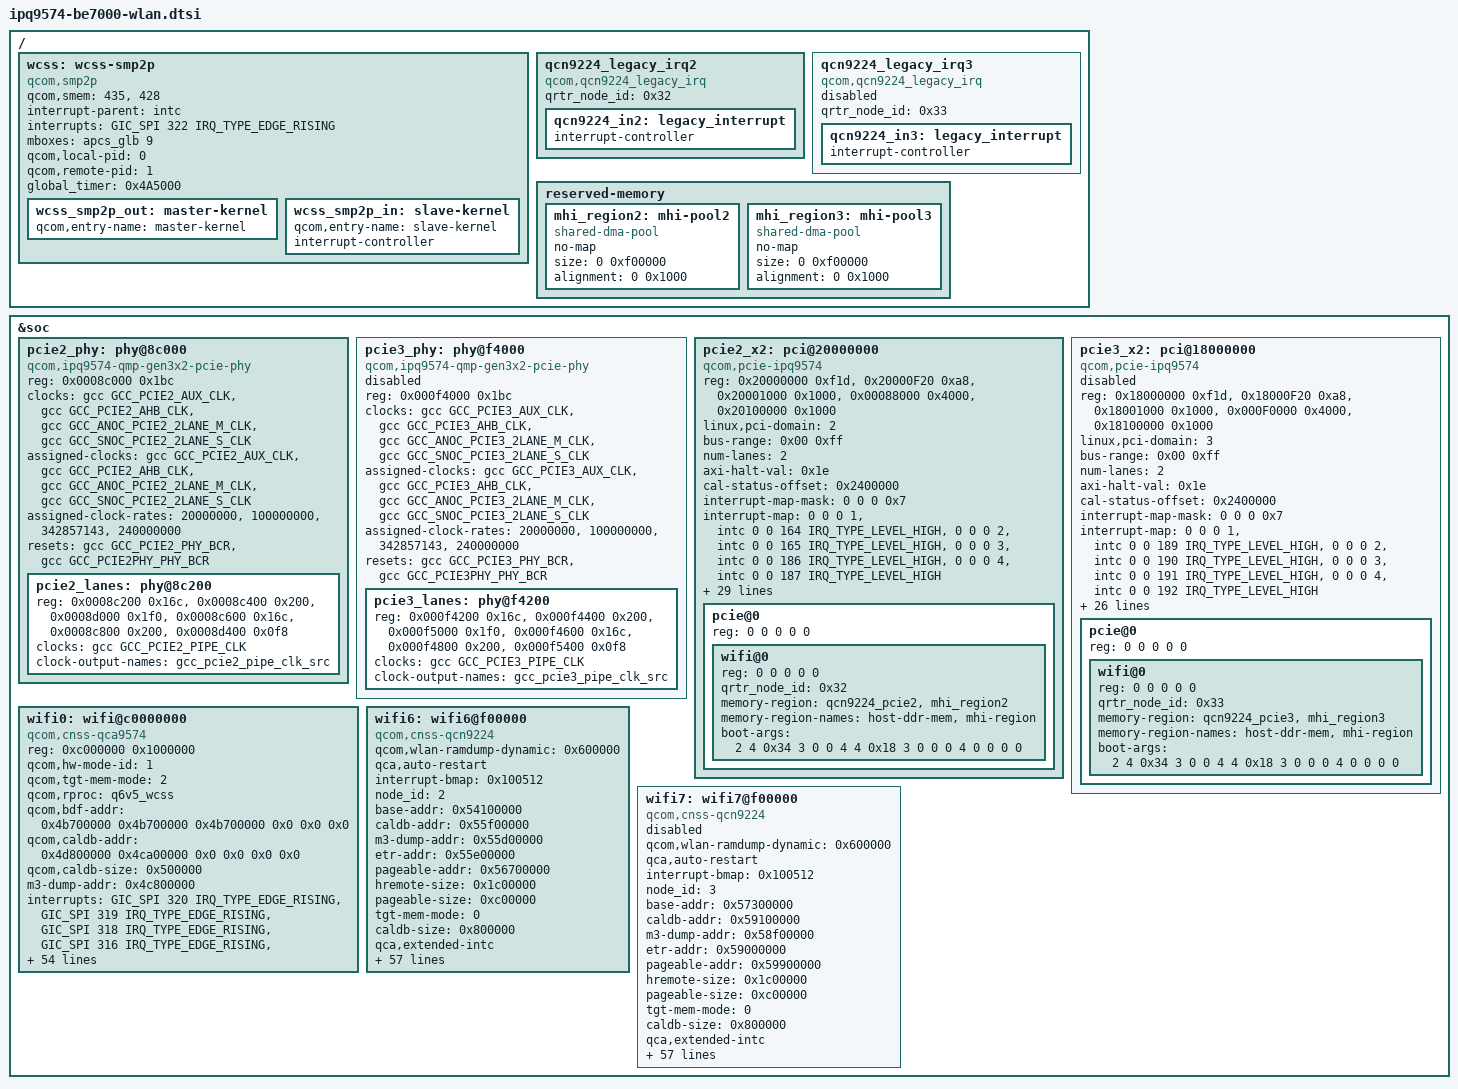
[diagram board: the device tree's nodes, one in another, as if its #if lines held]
// SPDX-License-Identifier: (GPL-2.0+ OR BSD-3-Clause)
/* IPQ9574 QSDK WLAN bindings, from NHSS.QSDK.14.0-01622-O.
 * Copyright (c) 2021-2024 Qualcomm Innovation Center, Inc. All rights reserved.
 */
/ {
	wcss: wcss-smp2p {
		compatible = "qcom,smp2p";
		qcom,smem = <435>, <428>;

		interrupt-parent = <&intc>;
		interrupts = <GIC_SPI 322 IRQ_TYPE_EDGE_RISING>;

		mboxes = <&apcs_glb 9>;

		qcom,local-pid = <0>;
		qcom,remote-pid = <1>;
		global_timer = <0x4A5000>;

		wcss_smp2p_out: master-kernel {
			qcom,entry-name = "master-kernel";
			#qcom,smem-state-cells = <1>;
		};

		wcss_smp2p_in: slave-kernel {
			qcom,entry-name = "slave-kernel";
			interrupt-controller;
			#interrupt-cells = <2>;
		};
	};
	qcn9224_legacy_irq2: qcn9224_legacy_irq2 {
		compatible = "qcom,qcn9224_legacy_irq";
		qrtr_node_id = <0x32>;
		status = "okay";

		qcn9224_in2: legacy_interrupt {
			interrupt-controller;
			#interrupt-cells = <2>;
		};
	};
	qcn9224_legacy_irq3: qcn9224_legacy_irq3 {
		compatible = "qcom,qcn9224_legacy_irq";
		qrtr_node_id = <0x33>;
		status = "disabled";

		qcn9224_in3: legacy_interrupt {
			interrupt-controller;
			#interrupt-cells = <2>;
		};
	};
};
&soc {
		pcie2_phy: phy@8c000 {
			compatible = "qcom,ipq9574-qmp-gen3x2-pcie-phy";
			reg = <0x0008c000 0x1bc>; /* Serdes PLL */
			#address-cells = <1>;
			#size-cells = <1>;
			ranges;

			clocks = <&gcc GCC_PCIE2_AUX_CLK>,
				 <&gcc GCC_PCIE2_AHB_CLK>,
				 <&gcc GCC_ANOC_PCIE2_2LANE_M_CLK>,
				 <&gcc GCC_SNOC_PCIE2_2LANE_S_CLK>;
			clock-names = "aux", "cfg_ahb", "anoc_lane", "snoc_lane";

			assigned-clocks = <&gcc GCC_PCIE2_AUX_CLK>,
					  <&gcc GCC_PCIE2_AHB_CLK>,
					  <&gcc GCC_ANOC_PCIE2_2LANE_M_CLK>,
					  <&gcc GCC_SNOC_PCIE2_2LANE_S_CLK>;
			assigned-clock-rates = <20000000>,
					       <100000000>,
					       <342857143>,
					       <240000000>;

			resets = <&gcc GCC_PCIE2_PHY_BCR>,
				 <&gcc GCC_PCIE2PHY_PHY_BCR>;
			reset-names = "phy", "common";

			status = "disabled";

			pcie2_lanes: phy@8c200 {
				reg = <0x0008c200 0x16c>, /* Serdes Tx0 */
				      <0x0008c400 0x200>, /* Serdes Rx0 */
				      <0x0008d000 0x1f0>, /* PCS: Lane0, COM, PCIE */
				      <0x0008c600 0x16c>, /* Serdes Tx1 */
				      <0x0008c800 0x200>, /* Serdes Rx1 */
				      <0x0008d400 0x0f8>; /* pcs_misc */

				#phy-cells = <0>;

				clocks = <&gcc GCC_PCIE2_PIPE_CLK>;
				clock-names = "pipe0";
				clock-output-names = "gcc_pcie2_pipe_clk_src";
				#clock-cells = <0>;
			};
		};
		pcie3_phy: phy@f4000 {
			compatible = "qcom,ipq9574-qmp-gen3x2-pcie-phy";
			reg = <0x000f4000 0x1bc>; /* Serdes PLL */
			#address-cells = <1>;
			#size-cells = <1>;
			ranges;

			clocks = <&gcc GCC_PCIE3_AUX_CLK>,
				 <&gcc GCC_PCIE3_AHB_CLK>,
				 <&gcc GCC_ANOC_PCIE3_2LANE_M_CLK>,
				 <&gcc GCC_SNOC_PCIE3_2LANE_S_CLK>;
			clock-names = "aux", "cfg_ahb", "anoc_lane", "snoc_lane";

			assigned-clocks = <&gcc GCC_PCIE3_AUX_CLK>,
					  <&gcc GCC_PCIE3_AHB_CLK>,
					  <&gcc GCC_ANOC_PCIE3_2LANE_M_CLK>,
					  <&gcc GCC_SNOC_PCIE3_2LANE_S_CLK>;
			assigned-clock-rates = <20000000>,
					       <100000000>,
					       <342857143>,
					       <240000000>;

			resets = <&gcc GCC_PCIE3_PHY_BCR>,
				 <&gcc GCC_PCIE3PHY_PHY_BCR>;
			reset-names = "phy", "common";

			status = "disabled";

			pcie3_lanes: phy@f4200 {
				reg = <0x000f4200 0x16c>, /* Serdes Tx0 */
				      <0x000f4400 0x200>, /* Serdes Rx0 */
				      <0x000f5000 0x1f0>, /* PCS: Lane0, COM, PCIE */
				      <0x000f4600 0x16c>, /* Serdes Tx1 */
				      <0x000f4800 0x200>, /* Serdes Rx1 */
				      <0x000f5400 0x0f8>; /* pcs_misc */

				#phy-cells = <0>;

				clocks = <&gcc GCC_PCIE3_PIPE_CLK>;
				clock-names = "pipe0";
				clock-output-names = "gcc_pcie3_pipe_clk_src";
				#clock-cells = <0>;
			};
		};
		pcie2_x2: pci@20000000 {
			compatible = "qcom,pcie-ipq9574";
			reg =  <0x20000000 0xf1d>,
			       <0x20000F20 0xa8>,
			       <0x20001000 0x1000>,
			       <0x00088000 0x4000>,
			       <0x20100000 0x1000>;
			reg-names = "dbi", "elbi", "atu", "parf", "config";
			device_type = "pci";
			linux,pci-domain = <2>;
			bus-range = <0x00 0xff>;
			num-lanes =<2>;
			#address-cells = <3>;
			#size-cells = <2>;
			axi-halt-val = <0x1e>; /* increase halt window size to 1GB */
			cal-status-offset = <0x2400000>;

			ranges = <0x81000000 0 0x20200000 0x20200000
				  0 0x00100000   /* downstream I/O */
				  0x82000000 0 0x20300000 0x20300000
				  0 0x07d00000>; /* non-prefetchable memory */

			#interrupt-cells = <1>;
			interrupt-map-mask = <0 0 0 0x7>;
			interrupt-map = <0 0 0 1 &intc 0 0 164
					 IRQ_TYPE_LEVEL_HIGH>, /* int_a */
					<0 0 0 2 &intc 0 0 165
					 IRQ_TYPE_LEVEL_HIGH>, /* int_b */
					<0 0 0 3 &intc 0 0 186
					 IRQ_TYPE_LEVEL_HIGH>, /* int_c */
					<0 0 0 4 &intc 0 0 187
					 IRQ_TYPE_LEVEL_HIGH>; /* int_d */

			interrupts = <GIC_SPI 125 IRQ_TYPE_LEVEL_HIGH>;
			interrupt-names = "global_irq";

			/* clocks and clock-names are used to enable the clock in CBCR */
			clocks = <&gcc GCC_PCIE2_AHB_CLK>,
				 <&gcc GCC_PCIE2_AUX_CLK>,
				 <&gcc GCC_PCIE2_AXI_M_CLK>,
				 <&gcc GCC_PCIE2_AXI_S_CLK>,
				 <&gcc GCC_PCIE2_AXI_S_BRIDGE_CLK>,
				 <&gcc GCC_PCIE2_RCHNG_CLK>;
			clock-names = "ahb",
				      "aux",
				      "axi_m",
				      "axi_s",
				      "axi_bridge",
				      "rchng";

			assigned-clocks = <&gcc GCC_PCIE2_AHB_CLK>,
					  <&gcc GCC_PCIE2_AUX_CLK>,
					  <&gcc GCC_PCIE2_AXI_M_CLK>,
					  <&gcc GCC_PCIE2_AXI_S_CLK>,
					  <&gcc GCC_PCIE2_AXI_S_BRIDGE_CLK>,
					  <&gcc GCC_PCIE2_RCHNG_CLK>;
			assigned-clock-rates = <100000000>,
					       <20000000>,
					       <342857143>,
					       <240000000>,
					       <240000000>,
					       <100000000>;

			resets = <&gcc GCC_PCIE2_PIPE_ARES>,
				 <&gcc GCC_PCIE2_CORE_STICKY_ARES>,
				 <&gcc GCC_PCIE2_AXI_S_STICKY_ARES>,
				 <&gcc GCC_PCIE2_AXI_S_ARES>,
				 <&gcc GCC_PCIE2_AXI_M_STICKY_ARES>,
				 <&gcc GCC_PCIE2_AXI_M_ARES>,
				 <&gcc GCC_PCIE2_AUX_ARES>,
				 <&gcc GCC_PCIE2_AHB_ARES>;
			reset-names = "pipe",
				      "sticky",
				      "axi_s_sticky",
				      "axi_s",
				      "axi_m_sticky",
				      "axi_m",
				      "aux",
				      "ahb";

			phys = <&pcie2_lanes>;
			phy-names = "pciephy";
			interconnects = <&gcc MASTER_ANOC_PCIE2 &gcc SLAVE_ANOC_PCIE2>,
					<&gcc MASTER_SNOC_PCIE2 &gcc SLAVE_SNOC_PCIE2>;
			interconnect-names = "pcie-mem", "cpu-pcie";
			msi-parent = <&v2m0>;
			status = "disabled";
		};
		pcie3_x2: pci@18000000 {
			compatible = "qcom,pcie-ipq9574";
			reg =  <0x18000000 0xf1d>,
			       <0x18000F20 0xa8>,
			       <0x18001000 0x1000>,
			       <0x000F0000 0x4000>,
			       <0x18100000 0x1000>;
			reg-names = "dbi", "elbi", "atu", "parf", "config";
			device_type = "pci";
			linux,pci-domain = <3>;
			bus-range = <0x00 0xff>;
			num-lanes = <2>;
			#address-cells = <3>;
			#size-cells = <2>;
			axi-halt-val = <0x1e>; /* increase halt window size to 1GB */
			cal-status-offset = <0x2400000>;

			ranges = <0x81000000 0 0x18200000 0x18200000
				  0 0x00100000   /* downstream I/O */
				  0x82000000 0 0x18300000 0x18300000
				  0 0x07d00000>; /* non-prefetchable memory */

			#interrupt-cells = <1>;
			interrupt-map-mask = <0 0 0 0x7>;
			interrupt-map = <0 0 0 1 &intc 0 0 189
					 IRQ_TYPE_LEVEL_HIGH>, /* int_a */
					<0 0 0 2 &intc 0 0 190
					 IRQ_TYPE_LEVEL_HIGH>, /* int_b */
					<0 0 0 3 &intc 0 0 191
					 IRQ_TYPE_LEVEL_HIGH>, /* int_c */
					<0 0 0 4 &intc 0 0 192
					 IRQ_TYPE_LEVEL_HIGH>; /* int_d */

			interrupts = <GIC_SPI 188 IRQ_TYPE_LEVEL_HIGH>;
			interrupt-names = "global_irq";

			/* clocks and clock-names are used to enable the clock in CBCR */
			clocks = <&gcc GCC_PCIE3_AHB_CLK>,
				 <&gcc GCC_PCIE3_AUX_CLK>,
				 <&gcc GCC_PCIE3_AXI_M_CLK>,
				 <&gcc GCC_PCIE3_AXI_S_CLK>,
				 <&gcc GCC_PCIE3_AXI_S_BRIDGE_CLK>,
				 <&gcc GCC_PCIE3_RCHNG_CLK>;
			clock-names = "ahb",
				      "aux",
				      "axi_m",
				      "axi_s",
				      "axi_bridge",
				      "rchng";

			assigned-clocks = <&gcc GCC_PCIE3_AHB_CLK>,
					  <&gcc GCC_PCIE3_AUX_CLK>,
					  <&gcc GCC_PCIE3_AXI_M_CLK>,
					  <&gcc GCC_PCIE3_AXI_S_CLK>,
					  <&gcc GCC_PCIE3_AXI_S_BRIDGE_CLK>,
					  <&gcc GCC_PCIE3_RCHNG_CLK>;
			assigned-clock-rates = <100000000>,
					       <20000000>,
					       <342857143>,
					       <240000000>,
					       <240000000>,
					       <100000000>;

			resets = <&gcc GCC_PCIE3_PIPE_ARES>,
				 <&gcc GCC_PCIE3_CORE_STICKY_ARES>,
				 <&gcc GCC_PCIE3_AXI_S_STICKY_ARES>,
				 <&gcc GCC_PCIE3_AXI_S_ARES>,
				 <&gcc GCC_PCIE3_AXI_M_STICKY_ARES>,
				 <&gcc GCC_PCIE3_AXI_M_ARES>,
				 <&gcc GCC_PCIE3_AUX_ARES>,
				 <&gcc GCC_PCIE3_AHB_ARES>;
			reset-names = "pipe",
				      "sticky",
				      "axi_s_sticky",
				      "axi_s",
				      "axi_m_sticky",
				      "axi_m",
				      "aux",
				      "ahb";

			phys = <&pcie3_lanes>;
			phy-names = "pciephy";
			msi-parent = <&v2m0>;
			status = "disabled";
		};
		wifi0: wifi@c0000000 {
			compatible = "qcom,cnss-qca9574", "qcom,ipq9574-wifi";
			reg = <0xc000000 0x1000000>;
			qcom,hw-mode-id = <1>;
		#ifdef __IPQ_MEM_PROFILE_256_MB__
			qcom,tgt-mem-mode = <2>;
		#elif __IPQ_MEM_PROFILE_512_MB__
			qcom,tgt-mem-mode = <1>;
		#else
			qcom,tgt-mem-mode = <0>;
		#endif
			qcom,rproc = <&q6v5_wcss>;
			qcom,bdf-addr = <0x4b700000 0x4b700000 0x4b700000
					 0x0 0x0 0x0>;
			qcom,caldb-addr = <0x4d800000 0x4ca00000 0x0
					   0x0 0x0 0x0>;
			qcom,caldb-size = <0x500000>;
		#ifdef __IPQ_MEM_PROFILE_512_MB__
			m3-dump-addr = <0x4c800000>;
		#else
			m3-dump-addr = <0x4d600000>;
		#endif
			interrupts = <GIC_SPI 320 IRQ_TYPE_EDGE_RISING>, /* o_wcss_apps_intr[0] =  */
				<GIC_SPI 319 IRQ_TYPE_EDGE_RISING>,
				<GIC_SPI 318 IRQ_TYPE_EDGE_RISING>,
				<GIC_SPI 316 IRQ_TYPE_EDGE_RISING>,
				<GIC_SPI 315 IRQ_TYPE_EDGE_RISING>,
				<GIC_SPI 314 IRQ_TYPE_EDGE_RISING>,
				<GIC_SPI 311 IRQ_TYPE_EDGE_RISING>,
				<GIC_SPI 310 IRQ_TYPE_EDGE_RISING>,
				<GIC_SPI 411 IRQ_TYPE_EDGE_RISING>,
				<GIC_SPI 410 IRQ_TYPE_EDGE_RISING>,
				<GIC_SPI 40 IRQ_TYPE_EDGE_RISING>,
				<GIC_SPI 39 IRQ_TYPE_EDGE_RISING>,
				<GIC_SPI 302 IRQ_TYPE_EDGE_RISING>,
				<GIC_SPI 301 IRQ_TYPE_EDGE_RISING>,
				<GIC_SPI 37 IRQ_TYPE_EDGE_RISING>,
				<GIC_SPI 36 IRQ_TYPE_EDGE_RISING>,
				<GIC_SPI 296 IRQ_TYPE_EDGE_RISING>,
				<GIC_SPI 295 IRQ_TYPE_EDGE_RISING>,
				<GIC_SPI 294 IRQ_TYPE_EDGE_RISING>,
				<GIC_SPI 293 IRQ_TYPE_EDGE_RISING>,
				<GIC_SPI 292 IRQ_TYPE_EDGE_RISING>,
				<GIC_SPI 291 IRQ_TYPE_EDGE_RISING>,
				<GIC_SPI 290 IRQ_TYPE_EDGE_RISING>,
				<GIC_SPI 289 IRQ_TYPE_EDGE_RISING>,
				<GIC_SPI 288 IRQ_TYPE_EDGE_RISING>, /* o_wcss_apps_intr[25] */
				<GIC_SPI 239 IRQ_TYPE_EDGE_RISING>,
				<GIC_SPI 236 IRQ_TYPE_EDGE_RISING>,
				<GIC_SPI 235 IRQ_TYPE_EDGE_RISING>,
				<GIC_SPI 234 IRQ_TYPE_EDGE_RISING>,
				<GIC_SPI 233 IRQ_TYPE_EDGE_RISING>,
				<GIC_SPI 232 IRQ_TYPE_EDGE_RISING>,
				<GIC_SPI 231 IRQ_TYPE_EDGE_RISING>,
				<GIC_SPI 230 IRQ_TYPE_EDGE_RISING>,
				<GIC_SPI 229 IRQ_TYPE_EDGE_RISING>,
				<GIC_SPI 228 IRQ_TYPE_EDGE_RISING>,
				<GIC_SPI 224 IRQ_TYPE_EDGE_RISING>,
				<GIC_SPI 223 IRQ_TYPE_EDGE_RISING>,
				<GIC_SPI 203 IRQ_TYPE_EDGE_RISING>,
				<GIC_SPI 183 IRQ_TYPE_EDGE_RISING>,
				<GIC_SPI 180 IRQ_TYPE_EDGE_RISING>,
				<GIC_SPI 179 IRQ_TYPE_EDGE_RISING>,
				<GIC_SPI 178 IRQ_TYPE_EDGE_RISING>,
				<GIC_SPI 177 IRQ_TYPE_EDGE_RISING>,
				<GIC_SPI 176 IRQ_TYPE_EDGE_RISING>,
				<GIC_SPI 163 IRQ_TYPE_EDGE_RISING>,
				<GIC_SPI 162 IRQ_TYPE_EDGE_RISING>,
				<GIC_SPI 160 IRQ_TYPE_EDGE_RISING>,
				<GIC_SPI 414 IRQ_TYPE_EDGE_RISING>,
				<GIC_SPI 159 IRQ_TYPE_EDGE_RISING>,
				<GIC_SPI 158 IRQ_TYPE_EDGE_RISING>,
				<GIC_SPI 157 IRQ_TYPE_EDGE_RISING>,
				<GIC_SPI 156 IRQ_TYPE_EDGE_RISING>; /* o_wcss_apps_intr[51] */

			interrupt-names = "misc-pulse1",
				"misc-latch",
				"sw-exception",
				"ce0",
				"ce1",
				"ce2",
				"ce3",
				"ce4",
				"ce5",
				"ce6",
				"ce7",
				"ce8",
				"ce9",
				"ce10",
				"ce11",
				"host2wbm-desc-feed",
				"host2reo-re-injection",
				"host2reo-command",
				"host2rxdma-monitor-ring3",
				"host2rxdma-monitor-ring2",
				"host2rxdma-monitor-ring1",
				"reo2ost-exception",
				"wbm2host-rx-release",
				"reo2host-status",
				"reo2host-destination-ring4",
				"reo2host-destination-ring3",
				"reo2host-destination-ring2",
				"reo2host-destination-ring1",
				"rxdma2host-monitor-destination-mac3",
				"rxdma2host-monitor-destination-mac2",
				"rxdma2host-monitor-destination-mac1",
				"ppdu-end-interrupts-mac3",
				"ppdu-end-interrupts-mac2",
				"ppdu-end-interrupts-mac1",
				"rxdma2host-monitor-status-ring-mac3",
				"rxdma2host-monitor-status-ring-mac2",
				"rxdma2host-monitor-status-ring-mac1",
				"host2rxdma-host-buf-ring-mac3",
				"host2rxdma-host-buf-ring-mac2",
				"host2rxdma-host-buf-ring-mac1",
				"rxdma2host-destination-ring-mac3",
				"rxdma2host-destination-ring-mac2",
				"rxdma2host-destination-ring-mac1",
				"host2tcl-input-ring4",
				"host2tcl-input-ring3",
				"host2tcl-input-ring2",
				"host2tcl-input-ring1",
				"wbm2host-tx-completions-ring4",
				"wbm2host-tx-completions-ring3",
				"wbm2host-tx-completions-ring2",
				"wbm2host-tx-completions-ring1",
				"tcl2host-status-ring";

			qcom,pta-num = <0>;
			qcom,coex-mode = <0x2>;
			qcom,bt-active-time = <0x12>;
			qcom,bt-priority-time = <0x0c>;
			qcom,coex-algo = <0x2>;
			qcom,pta-priority = <0x80800505>;
			status = "disabled";
		};
		wifi6: wifi6@f00000 {
			compatible  = "qcom,cnss-qcn9224";
			qcom,wlan-ramdump-dynamic = <0x600000>;
			qca,auto-restart;
			interrupt-bmap = <0x100512>;
			node_id = <2>;
#ifdef __IPQ_MEM_PROFILE_512_MB__
			/* qcn9224 tgt-mem-mode=1 layout - 27MB
			 * +=========+==============+=========+
			 * |  Region | Start Offset |   Size  |
			 * +---------+--------------+---------+
			 * | HREMOTE |  0x50500000  |   13MB  |
			 * +---------+--------------+---------+
			 * |  Caldb  |  0x51200000  |   8MB   |
			 * +---------+--------------+---------+
			 * | M3 Dump |  0x51A00000  |   1MB   |
			 * +---------+--------------+---------+
			 * |   ETR   |  0x51B00000  |   1MB   |
			 * +---------+--------------+---------+
			 * |Pageable |  0x51C00000  |   4MB   |
			 * +==================================+
			 */
			base-addr = <0x50500000>;
			caldb-addr = <0x51200000>;
			m3-dump-addr = <0x51A00000>;
			etr-addr = <0x51B00000>;
			pageable-addr = <0x51C00000>;
			hremote-size = <0xD00000>;
			pageable-size = <0x400000>;
			tgt-mem-mode = <0x1>;
#else
			/* qcn9224 tgt-mem-mode=0 layout - 36MB
			 * +=========+==============+=========+
			 * |  Region | Start Offset |   Size  |
			 * +---------+--------------+---------+
			 * | HREMOTE |  0x52500000  |   17MB  |
			 * +---------+--------------+---------+
			 * |  Caldb  |  0x53600000  |   8MB   |
			 * +---------+--------------+---------+
			 * | M3 Dump |  0x53E00000  |   1MB   |
			 * +---------+--------------+---------+
			 * |   ETR   |  0x53F00000  |   1MB   |
			 * +---------+--------------+---------+
			 * |Pageable |  0x54000000  |   9MB   |
			 * +==================================+
			 */
			base-addr = <0x52500000>;
			caldb-addr = <0x53600000>;
			m3-dump-addr = <0x53E00000>;
			etr-addr = <0x53F00000>;
			pageable-addr = <0x54000000>;
			hremote-size = <0x1100000>;
			pageable-size = <0x900000>;
			tgt-mem-mode = <0x0>;
#endif
			caldb-size = <0x800000>;
			qca,extended-intc;
			early_cal = <&pcie2_x2>;
			interrupts-extended =
				<&qcn9224_in2 5 0>,
				<&qcn9224_in2 6 0>,
				<&qcn9224_in2 7 0>,
				<&qcn9224_in2 8 0>,
				<&qcn9224_in2 9 0>,
				<&qcn9224_in2 10 0>,
				<&qcn9224_in2 11 0>,
				<&qcn9224_in2 12 0>,
				<&qcn9224_in2 13 0>,
				<&qcn9224_in2 14 0>,
				<&qcn9224_in2 15 0>,
				<&qcn9224_in2 16 0>,
				<&qcn9224_in2 17 0>,
				<&qcn9224_in2 18 0>,
				<&qcn9224_in2 19 0>,
				<&qcn9224_in2 20 0>,
				<&qcn9224_in2 49 0>,
				<&qcn9224_in2 48 0>,
				<&qcn9224_in2 47 0>,
				<&qcn9224_in2 46 0>,
				<&qcn9224_in2 45 0>,
				<&qcn9224_in2 44 0>,
				<&qcn9224_in2 43 0>,
				<&qcn9224_in2 42 0>,
				<&qcn9224_in2 50 0>,
				<&qcn9224_in2 52 0>,
				<&qcn9224_in2 51 0>,
				<&qcn9224_in2 30 0>,
				<&qcn9224_in2 29 0>,
				<&qcn9224_in2 28 0>,
				<&qcn9224_in2 27 0>,
				<&qcn9224_in2 26 0>,
				<&qcn9224_in2 25 0>,
				<&qcn9224_in2 31 0>,
				<&qcn9224_in2 80 0>,
				<&qcn9224_in2 71 0>,
				<&qcn9224_in2 96 0>,
				<&qcn9224_in2 97 0>,
				<&qcn9224_in2 67 0>,
				<&qcn9224_in2 100 0>,
				<&qcn9224_in2 99 0>,
				<&qcn9224_in2 68 0>,
				<&qcn9224_in2 69 0>,
				<&qcn9224_in2 121 0>,
				<&qcn9224_in2 119 0>,
				<&qcn9224_in2 122 0>,
				<&qcn9224_in2 120 0>,
				<&qcn9224_in2 116 0>,
				<&qcn9224_in2 113 0>,
				<&qcn9224_in2 115 0>,
				<&qcn9224_in2 112 0>,
				<&qcn9224_in2 114 0>,
				<&qcn9224_in2 111 0>,
				<&qcn9224_in2 110 0>,
				<&qcn9224_in2 109 0>,
				<&qcn9224_in2 108 0>,
				<&qcn9224_in2 39 0>,
				<&qcn9224_in2 38 0>,
				<&qcn9224_in2 37 0>,
				<&qcn9224_in2 36 0>,
				<&qcn9224_in2 35 0>,
				<&qcn9224_in2 34 0>,
				<&qcn9224_in2 33 0>,
				<&qcn9224_in2 41 0>,
				<&qcn9224_in2 40 0>,
				<&qcn9224_in2 32 0>,
				<&qcn9224_in2 24 0>,
				<&qcn9224_in2 23 0>,
				<&qcn9224_in2 22 0>,
				<&qcn9224_in2 21 0>,
				<&qcn9224_in2 66 0>,
				<&qcn9224_in2 78 0>,
				<&qcn9224_in2 117 0>,
				<&qcn9224_in2 118 0>,
				<&qcn9224_in2 61 0>,
				<&qcn9224_in2 60 0>,
				<&qcn9224_in2 57 0>,
				<&qcn9224_in2 56 0>,
				<&qcn9224_in2 63 0>,
				<&qcn9224_in2 62 0>,
				<&qcn9224_in2 59 0>,
				<&qcn9224_in2 58 0>,
				<&qcn9224_in2 65 0>,
				<&qcn9224_in2 83 0>,
				<&qcn9224_in2 75 0>,
				<&qcn9224_in2 82 0>,
				<&qcn9224_in2 81 0>,
				<&qcn9224_in2 74 0>,
				<&qcn9224_in2 73 0>,
				<&qcn9224_in2 72 0>,
				<&qcn9224_in2 98 0>,
				<&qcn9224_in2 107 0>,
				<&qcn9224_in2 106 0>,
				<&qcn9224_in2 105 0>,
				<&qcn9224_in2 104 0>,
				<&qcn9224_in2 103 0>,
				<&qcn9224_in2 102 0>,
				<&qcn9224_in2 101 0>,
				<&qcn9224_in2 76 0>,
				<&qcn9224_in2 77 0>,
				<&qcn9224_in2 143 0>,
				<&qcn9224_in2 142 0>,
				<&qcn9224_in2 141 0>,
				<&intc GIC_SPI 164 IRQ_TYPE_LEVEL_HIGH>;

			interrupt-names = "ce0",
				"ce1",
				"ce2",
				"ce3",
				"ce4",
				"ce5",
				"ce6",
				"ce7",
				"ce8",
				"ce9",
				"ce10",
				"ce11",
				"ce12",
				"ce13",
				"ce14",
				"ce15",
				"reo2sw8_intr2",
				"reo2sw7_intr2",
				"reo2sw6_intr2",
				"reo2sw5_intr2",
				"reo2sw4_intr2",
				"reo2sw3_intr2",
				"reo2sw2_intr2",
				"reo2sw1_intr2",
				"reo2sw0_intr2",
				"reo2sw8_intr",
				"reo2sw7_intr",
				"reo2sw6_inrr",
				"reo2sw5_intr",
				"reo2sw4_intr",
				"reo2sw3_intr",
				"reo2sw2_intr",
				"reo2sw1_intr",
				"reo2sw0_intr",
				"reo2status_intr2",
				"reo_status",
				"reo2rxdma_out_2",
				"reo2rxdma_out_1",
				"reo_cmd",
				"sw2reo6",
				"sw2reo5",
				"sw2reo1",
				"sw2reo",
				"rxdma2reo_mlo_0_dst_ring1",
				"rxdma2reo_mlo_0_dst_ring0",
				"rxdma2reo_mlo_1_dst_ring1",
				"rxdma2reo_mlo_1_dst_ring0",
				"rxdma2reo_dst_ring1",
				"rxdma2reo_dst_ring0",
				"rxdma2sw_dst_ring1",
				"rxdma2sw_dst_ring0",
				"rxdma2release_dst_ring1",
				"rxdma2release_dst_ring0",
				"sw2rxdma_2_src_ring",
				"sw2rxdma_1_src_ring",
				"sw2rxdma_0",
				"wbm2sw6_release2",
				"wbm2sw5_release2",
				"wbm2sw4_release2",
				"wbm2sw3_release2",
				"wbm2sw2_release2",
				"wbm2sw1_release2",
				"wbm2sw0_release2",
				"wbm2sw6_release",
				"wbm2sw5_release",
				"wbm2sw4_release",
				"wbm2sw3_release",
				"wbm2sw2_release",
				"wbm2sw1_release",
				"wbm2sw0_release",
				"wbm2sw_link",
				"wbm_error_release",
				"sw2txmon_src_ring",
				"sw2rxmon_src_ring",
				"txmon2sw_p1_intr1",
				"txmon2sw_p1_intr0",
				"txmon2sw_p0_dest1",
				"txmon2sw_p0_dest0",
				"rxmon2sw_p1_intr1",
				"rxmon2sw_p1_intr0",
				"rxmon2sw_p0_dest1",
				"rxmon2sw_p0_dest0",
				"sw_release",
				"sw2tcl_credit2",
				"sw2tcl_credit",
				"sw2tcl4",
				"sw2tcl5",
				"sw2tcl3",
				"sw2tcl2",
				"sw2tcl1",
				"sw2wbm1",
				"misc_8",
				"misc_7",
				"misc_6",
				"misc_5",
				"misc_4",
				"misc_3",
				"misc_2",
				"misc_1",
				"misc_0",
				"mhi2",
				"mhi1",
				"mhi0",
				"inta";

			status = "disabled";
		};
		wifi7: wifi7@f00000 {
			compatible  = "qcom,cnss-qcn9224";
			qcom,wlan-ramdump-dynamic = <0x600000>;
			qca,auto-restart;
			interrupt-bmap = <0x100512>;
			node_id = <3>;
#ifdef __IPQ_MEM_PROFILE_512_MB__
			/* qcn9224 tgt-mem-mode=1 layout - 27MB
			 * +=========+==============+=========+
			 * |  Region | Start Offset |   Size  |
			 * +---------+--------------+---------+
			 * | HREMOTE |  0x52000000  |   13MB  |
			 * +---------+--------------+---------+
			 * |  Caldb  |  0x52D00000  |   8MB   |
			 * +---------+--------------+---------+
			 * | M3 Dump |  0x53500000  |   1MB   |
			 * +---------+--------------+---------+
			 * |   ETR   |  0x53600000  |   1MB   |
			 * +---------+--------------+---------+
			 * |Pageable |  0x53700000  |   4MB   |
			 * +==================================+
			 */
			base-addr = <0x52000000>;
			caldb-addr = <0x52D00000>;
			m3-dump-addr = <0x53500000>;
			etr-addr = <0x53600000>;
			pageable-addr = <0x53700000>;
			hremote-size = <0xD00000>;
			pageable-size = <0x400000>;
			tgt-mem-mode = <0x1>;
#else
			/* qcn9224 tgt-mem-mode=0 layout - 36MB
			 * +=========+==============+=========+
			 * |  Region | Start Offset |   Size  |
			 * +---------+--------------+---------+
			 * | HREMOTE |  0x54900000  |   17MB  |
			 * +---------+--------------+---------+
			 * |  Caldb  |  0x55A00000  |   8MB   |
			 * +---------+--------------+---------+
			 * | M3 Dump |  0x56200000  |   1MB   |
			 * +---------+--------------+---------+
			 * |   ETR   |  0x56300000  |   1MB   |
			 * +---------+--------------+---------+
			 * |Pageable |  0x56400000  |   9MB   |
			 * +==================================+
			 */
			base-addr = <0x54900000>;
			caldb-addr = <0x55A00000>;
			m3-dump-addr = <0x56200000>;
			etr-addr = <0x56300000>;
			pageable-addr = <0x56400000>;
			hremote-size = <0x1100000>;
			pageable-size = <0x900000>;
			tgt-mem-mode = <0x0>;
#endif
			caldb-size = <0x800000>;
			qca,extended-intc;
			early_cal = <&pcie3_x2>;
			interrupts-extended =
				<&qcn9224_in3 5 0>,
				<&qcn9224_in3 6 0>,
				<&qcn9224_in3 7 0>,
				<&qcn9224_in3 8 0>,
				<&qcn9224_in3 9 0>,
				<&qcn9224_in3 10 0>,
				<&qcn9224_in3 11 0>,
				<&qcn9224_in3 12 0>,
				<&qcn9224_in3 13 0>,
				<&qcn9224_in3 14 0>,
				<&qcn9224_in3 15 0>,
				<&qcn9224_in3 16 0>,
				<&qcn9224_in3 17 0>,
				<&qcn9224_in3 18 0>,
				<&qcn9224_in3 19 0>,
				<&qcn9224_in3 20 0>,
				<&qcn9224_in3 49 0>,
				<&qcn9224_in3 48 0>,
				<&qcn9224_in3 47 0>,
				<&qcn9224_in3 46 0>,
				<&qcn9224_in3 45 0>,
				<&qcn9224_in3 44 0>,
				<&qcn9224_in3 43 0>,
				<&qcn9224_in3 42 0>,
				<&qcn9224_in3 50 0>,
				<&qcn9224_in3 52 0>,
				<&qcn9224_in3 51 0>,
				<&qcn9224_in3 30 0>,
				<&qcn9224_in3 29 0>,
				<&qcn9224_in3 28 0>,
				<&qcn9224_in3 27 0>,
				<&qcn9224_in3 26 0>,
				<&qcn9224_in3 25 0>,
				<&qcn9224_in3 31 0>,
				<&qcn9224_in3 80 0>,
				<&qcn9224_in3 71 0>,
				<&qcn9224_in3 96 0>,
				<&qcn9224_in3 97 0>,
				<&qcn9224_in3 67 0>,
				<&qcn9224_in3 100 0>,
				<&qcn9224_in3 99 0>,
				<&qcn9224_in3 68 0>,
				<&qcn9224_in3 69 0>,
				<&qcn9224_in3 121 0>,
				<&qcn9224_in3 119 0>,
				<&qcn9224_in3 122 0>,
				<&qcn9224_in3 120 0>,
				<&qcn9224_in3 116 0>,
				<&qcn9224_in3 113 0>,
				<&qcn9224_in3 115 0>,
				<&qcn9224_in3 112 0>,
				<&qcn9224_in3 114 0>,
				<&qcn9224_in3 111 0>,
				<&qcn9224_in3 110 0>,
				<&qcn9224_in3 109 0>,
				<&qcn9224_in3 108 0>,
				<&qcn9224_in3 39 0>,
				<&qcn9224_in3 38 0>,
				<&qcn9224_in3 37 0>,
				<&qcn9224_in3 36 0>,
				<&qcn9224_in3 35 0>,
				<&qcn9224_in3 34 0>,
				<&qcn9224_in3 33 0>,
				<&qcn9224_in3 41 0>,
				<&qcn9224_in3 40 0>,
				<&qcn9224_in3 32 0>,
				<&qcn9224_in3 24 0>,
				<&qcn9224_in3 23 0>,
				<&qcn9224_in3 22 0>,
				<&qcn9224_in3 21 0>,
				<&qcn9224_in3 66 0>,
				<&qcn9224_in3 78 0>,
				<&qcn9224_in3 117 0>,
				<&qcn9224_in3 118 0>,
				<&qcn9224_in3 61 0>,
				<&qcn9224_in3 60 0>,
				<&qcn9224_in3 57 0>,
				<&qcn9224_in3 56 0>,
				<&qcn9224_in3 63 0>,
				<&qcn9224_in3 62 0>,
				<&qcn9224_in3 59 0>,
				<&qcn9224_in3 58 0>,
				<&qcn9224_in3 65 0>,
				<&qcn9224_in3 83 0>,
				<&qcn9224_in3 75 0>,
				<&qcn9224_in3 82 0>,
				<&qcn9224_in3 81 0>,
				<&qcn9224_in3 74 0>,
				<&qcn9224_in3 73 0>,
				<&qcn9224_in3 72 0>,
				<&qcn9224_in3 98 0>,
				<&qcn9224_in3 107 0>,
				<&qcn9224_in3 106 0>,
				<&qcn9224_in3 105 0>,
				<&qcn9224_in3 104 0>,
				<&qcn9224_in3 103 0>,
				<&qcn9224_in3 102 0>,
				<&qcn9224_in3 101 0>,
				<&qcn9224_in3 76 0>,
				<&qcn9224_in3 77 0>,
				<&qcn9224_in3 143 0>,
				<&qcn9224_in3 142 0>,
				<&qcn9224_in3 141 0>,
				<&intc GIC_SPI 189 IRQ_TYPE_LEVEL_HIGH>;

			interrupt-names = "ce0",
				"ce1",
				"ce2",
				"ce3",
				"ce4",
				"ce5",
				"ce6",
				"ce7",
				"ce8",
				"ce9",
				"ce10",
				"ce11",
				"ce12",
				"ce13",
				"ce14",
				"ce15",
				"reo2sw8_intr2",
				"reo2sw7_intr2",
				"reo2sw6_intr2",
				"reo2sw5_intr2",
				"reo2sw4_intr2",
				"reo2sw3_intr2",
				"reo2sw2_intr2",
				"reo2sw1_intr2",
				"reo2sw0_intr2",
				"reo2sw8_intr",
				"reo2sw7_intr",
				"reo2sw6_inrr",
				"reo2sw5_intr",
				"reo2sw4_intr",
				"reo2sw3_intr",
				"reor",
				"reo2sw1_intr",
				"reo2sw0_intr",
				"reo2status_intr2",
				"reo_status",
				"reo2rxdma_out_2",
				"reo2rxdma_out_1",
				"reo_cmd",
				"sw2reo6",
				"sw2reo5",
				"sw2reo1",
				"sw2reo",
				"rxdma2reo_mlo_0_dst_ring1",
				"rxdma2reo_mlo_0_dst_ring0",
				"rxdma2reo_mlo_1_dst_ring1",
				"rxdma2reo_mlo_1_dst_ring0",
				"rxdma2reo_dst_ring1",
				"rxdma2reo_dst_ring0",
				"rxdma2sw_dst_ring1",
				"rxdma2sw_dst_ring0",
				"rxdma2release_dst_ring1",
				"rxdma2release_dst_ring0",
				"sw2rxdma_2_src_ring",
				"sw2rxdma_1_src_ring",
				"sw2rxdma_0",
				"wbm2sw6_release2",
				"wbm2sw5_release2",
				"wbm2sw4_release2",
				"wbm2sw3_release2",
				"wbm2sw2_release2",
				"wbm2sw1_release2",
				"wbm2sw0_release2",
				"wbm2sw6_release",
				"wbm2sw5_release",
				"wbm2sw4_release",
				"wbm2sw3_release",
				"wbm2sw2_release",
				"wbm2sw1_release",
				"wbm2sw0_release",
				"wbm2sw_link",
				"wbm_error_release",
				"sw2txmon_src_ring",
				"sw2rxmon_src_ring",
				"txmon2sw_p1_intr1",
				"txmon2sw_p1_intr0",
				"txmon2sw_p0_dest1",
				"txmon2sw_p0_dest0",
				"rxmon2sw_p1_intr1",
				"rxmon2sw_p1_intr0",
				"rxmon2sw_p0_dest1",
				"rxmon2sw_p0_dest0",
				"sw_release",
				"sw2tcl_credit2",
				"sw2tcl_credit",
				"sw2tcl4",
				"sw2tcl5",
				"sw2tcl3",
				"sw2tcl2",
				"sw2tcl1",
				"sw2wbm1",
				"misc_8",
				"misc_7",
				"misc_6",
				"misc_5",
				"misc_4",
				"misc_3",
				"misc_2",
				"misc_1",
				"misc_0",
				"mhi2",
				"mhi1",
				"mhi0",
				"inta";

			status = "disabled";
		};
};

/* BE7000 stock WLAN memory pools and radio configuration. */
/ {
	reserved-memory {
		mhi_region2: mhi-pool2 {
			compatible = "shared-dma-pool";
			no-map;
			size = <0 0xf00000>;
			alignment = <0 0x1000>;
		};
		mhi_region3: mhi-pool3 {
			compatible = "shared-dma-pool";
			no-map;
			size = <0 0xf00000>;
			alignment = <0 0x1000>;
		};
	};
};

&pcie2_phy { status = "okay"; };
/* PCIe3 is disabled in this board's QFPROM fuses. */
&pcie3_phy { status = "disabled"; };
&pcie2_x2 {
	perst-gpios = <&tlmm 29 GPIO_ACTIVE_LOW>;
	status = "okay";
	pcie@0 {
		device_type = "pci";
		reg = <0 0 0 0 0>;
		#address-cells = <3>;
		#size-cells = <2>;
		ranges;
		wifi@0 {
			reg = <0 0 0 0 0>;
			qrtr_node_id = <0x32>;
			memory-region = <&qcn9224_pcie2>, <&mhi_region2>;
			memory-region-names = "host-ddr-mem", "mhi-region";
			boot-args = <2 4 0x34 3 0 0 4 4 0x18 3 0 0 0 4 0 0 0 0>;
		};
	};
};
&pcie3_x2 {
	perst-gpios = <&tlmm 32 GPIO_ACTIVE_LOW>;
	status = "disabled";
	pcie@0 {
		device_type = "pci";
		reg = <0 0 0 0 0>;
		#address-cells = <3>;
		#size-cells = <2>;
		ranges;
		wifi@0 {
			reg = <0 0 0 0 0>;
			qrtr_node_id = <0x33>;
			memory-region = <&qcn9224_pcie3>, <&mhi_region3>;
			memory-region-names = "host-ddr-mem", "mhi-region";
			boot-args = <2 4 0x34 3 0 0 4 4 0x18 3 0 0 0 4 0 0 0 0>;
		};
	};
};

&wifi0 { status = "okay"; };
&wifi6 {
	qrtr_node_id = <0x32>;
	base-addr = <0x54100000>;
	hremote-size = <0x1c00000>;
	m3-dump-addr = <0x55d00000>;
	etr-addr = <0x55e00000>;
	caldb-addr = <0x55f00000>;
	caldb-size = <0x800000>;
	pageable-addr = <0x56700000>;
	pageable-size = <0xc00000>;
	tgt-mem-mode = <0>;
	hremote_node = <&qcn9224_pcie2>;
	board_id = <4>;
	status = "okay";
};
&wifi7 {
	qrtr_node_id = <0x33>;
	base-addr = <0x57300000>;
	hremote-size = <0x1c00000>;
	m3-dump-addr = <0x58f00000>;
	etr-addr = <0x59000000>;
	caldb-addr = <0x59100000>;
	caldb-size = <0x800000>;
	pageable-addr = <0x59900000>;
	pageable-size = <0xc00000>;
	tgt-mem-mode = <0>;
	hremote_node = <&qcn9224_pcie3>;
	board_id = <2>;
	status = "disabled";
};
